# ATtiny828 register map
Vendor: Atmel; File version: 1.0
CPU: other r0p0, little endian, no MPU, no FPU, 4 interrupt priority bits
Registers are 8-bit, read-write, reset 0x0 unless marked. A register's access mark holds for its fields unless they carry their own. Offsets are from the block's base; lines under a group give offsets from that group; [hi:lo] are bit positions; {n}, {i} and the like mark numbered series; 'fields as' and 'values as' point back to an identical list; <NAME> marks a mode.

## Memory map
0x00000000 FUSE size 0x3 — Fuses
0x00000000 LOCKBIT size 0x1 — Lockbits
0x00000020 PORTA size 0x4 — I/O Port
0x00000024 PORTB size 0x4 — I/O Port
0x00000028 PORTC blocks up to offset 0xD — I/O Port
0x0000002C PORTD size 0x4 — I/O Port
0x00000035 TC0 blocks up to offset 0x3A — Timer/Counter, 8-bit
0x00000036 TC1 blocks up to offset 0x56 — Timer/Counter, 16-bit
0x0000003B EXINT blocks up to offset 0x39 — External Interrupts
0x0000003E CPU blocks up to offset 0xB4 — CPU Registers
0x0000003F EEPROM blocks up to offset 0x3
0x0000004C SPI size 0x3 — Serial Peripheral Interface
0x0000004F AC size 0x2 — Analog Comparator
0x00000060 WDT size 0x1 — Watchdog Timer
0x00000078 ADC blocks up to offset 0x68 — Analog-to-Digital Converter
0x000000B8 TWI size 0x6 — Two Wire Serial Interface
0x000000C0 USART size 0x7
0x000000E2 TOCPM blocks up to offset 0x8 — Timer/Counter Output Compare Pin

## Interrupts
0 RESET (CPU) — External Pin, Power-on Reset, Brown-out Reset and Watchdog Reset
1 INT0 (CPU) — External Interrupt Request 0
2 INT1 (CPU) — External Interrupt Request 1
3 PCINT0 (CPU) — Pin Change Interrupt Request 0
4 PCINT1 (CPU) — Pin Change Interrupt Request 1
5 PCINT2 (CPU) — Pin Change Interrupt Request 2
6 PCINT3 (CPU) — Pin Change Interrupt Request 3
7 WDT (CPU) — Watchdog Time-out Interrupt
8 TIMER1_CAPT (CPU) — Timer/Counter1 Capture Event
9 TIMER1_COMPA (CPU) — Timer/Counter1 Compare Match A
10 TIMER1_COMPB (CPU) — Timer/Counter1 Compare Match B
11 TIMER1_OVF (CPU) — Timer/Counter1 Overflow
12 TIMER0_COMPA (CPU) — Timer/Counter0 Compare Match A
13 TIMER0_COMPB (CPU) — Timer/Counter0 Compare Match B
14 TIMER0_OVF (CPU) — Timer/Counter0 Overflow
15 SPI_STC (CPU) — SPI Serial Transfer Complete
16 USART_START (CPU)
17 USART_RX (CPU) — USART Rx Complete
18 USART_UDRE (CPU) — USART, Data Register Empty
19 USART_TX (CPU) — USART Tx Complete
20 ADC (CPU) — ADC Conversion Complete
21 EE_READY (CPU) — EEPROM Ready
22 ANALOG_COMP (CPU) — Analog Comparator
23 TWI_SLAVE (CPU) — Two-wire Serial Interface
24 SPM_Ready (CPU) — Store Program Memory Read
25 QTRIP (CPU) — Touch Sensing

## AC — Analog Comparator
Base 0x0000004F
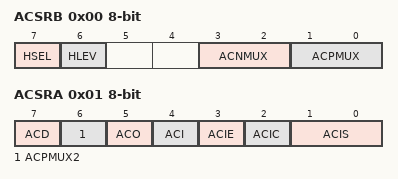
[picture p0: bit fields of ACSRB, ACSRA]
0x00 ACSRB — Analog Comparator Control And Status Register B
  [7] HSEL — Hysteresis Select
  [6] HLEV — Hysteresis Level
  [3:2] ACNMUX — Analog Comparator Negative Input Multiplexer
  [1:0] ACPMUX — Analog Comparator Positive Input Multiplexer Bits 1:0
0x01 ACSRA — Analog Comparator Control And Status Register A
  [7] ACD — Analog Comparator Disable
  [6] ACPMUX2 — Analog Comparator Positive Input Multiplexer Bit 2
  [5] ACO — Analog Compare Output
  [4] ACI — Analog Comparator Interrupt Flag
  [3] ACIE — Analog Comparator Interrupt Enable
  [2] ACIC — Analog Comparator Input Capture Enable
  [1:0] ACIS — Analog Comparator Interrupt Mode Select bits
    0=INTERRUPT_ON_TOGGLE; 2=INTERRUPT_ON_FALLING_EDGE; 3=INTERRUPT_ON_RISING_EDGE

## ADC — Analog-to-Digital Converter
Base 0x00000078
0x00 ADC 16-bit (reset mask 0xFF) — ADC Data Register Bytes
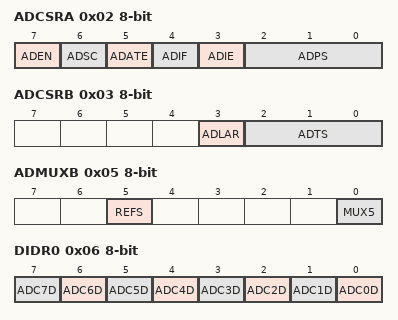
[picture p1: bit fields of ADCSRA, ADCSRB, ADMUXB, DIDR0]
0x02 ADCSRA — The ADC Control and Status register
  [7] ADEN — ADC Enable
  [6] ADSC — ADC Start Conversion
  [5] ADATE — ADC Auto Trigger Enable
  [4] ADIF — ADC Interrupt Flag
  [3] ADIE — ADC Interrupt Enable
  [2:0] ADPS — ADC Prescaler Select Bits
    1=2; 2=4; 3=8; 4=16; 5=32; 6=64; 7=128
0x03 ADCSRB — ADC Control and Status Register B
  [3] ADLAR
  [2:0] ADTS — ADC Auto Trigger Sources
    0=FREE_RUNNING_MODE; 1=ANALOG_COMPARATOR; 2=EXTERNAL_INTERRUPT_REQUEST_0; 3=TIMER_COUNTER0_COMPARE_MATCH_A; 4=TIMER_COUNTER0_OVERFLOW; 5=TIMER_COUNTER1_COMPARE_MATCH_B; 6=TIMER_COUNTER1_OVERFLOW; 7=TIMER_COUNTER1_CAPTURE_EVENT
0x04 ADMUXA — The ADC multiplexer Selection Register A
  [4:0] MUX — Analog Channel Selection Bits 4:0
0x05 ADMUXB — The ADC multiplexer Selection Register B
  [5] REFS — Reference Selection Bit
  [0] MUX5 — Analog Channel Selection Bit 5
0x06 DIDR0 — Digital Input Disable Register 0
  [n] ADC{n}D (n=0..7) — ADC{n} Digital input Disable
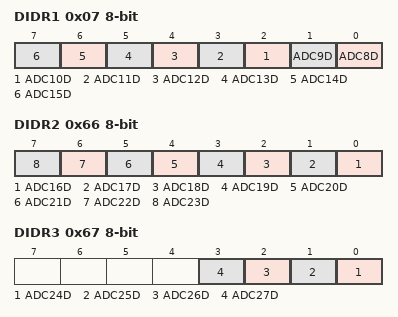
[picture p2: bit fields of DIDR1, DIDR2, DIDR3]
0x07 DIDR1 — Digital Input Disable Register 1
  [n-8] ADC{n}D (n=8..15) — ADC{n} Digital input Disable
0x66 DIDR2 — Digital Input Disable Register 2
  [n-16] ADC{n}D (n=16..23) — ADC{n} Digital input Disable
0x67 DIDR3 — Digital Input Disable Register 2
  [n-24] ADC{n}D (n=24..27) — ADC{n} Digital input Disable
